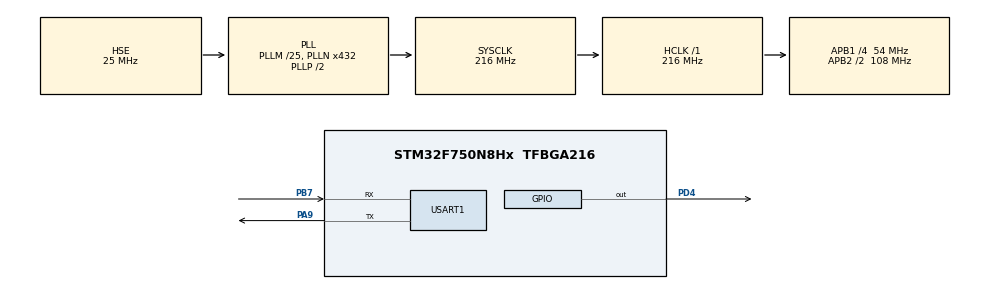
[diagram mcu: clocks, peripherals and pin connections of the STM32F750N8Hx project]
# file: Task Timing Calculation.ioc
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FREERTOS.Tasks01=defaultTask,24,128,StartDefaultTask,Default,NULL,Dynamic,NULL,NULL
Mcu.Family=STM32F7
Mcu.Name=STM32F750N8Hx
Mcu.Package=TFBGA216
NVIC.PriorityGroup=NVIC_PRIORITYGROUP_4
NVIC.TIM1_UP_TIM10_IRQn=true\:15\:0\:false\:false\:true\:false\:false\:true
NVIC.TimeBase=TIM1_UP_TIM10_IRQn
NVIC.TimeBaseIP=TIM1
PA9.Mode=Asynchronous
PA9.Signal=USART1_TX
PB7.Mode=Asynchronous
PB7.Signal=USART1_RX
PD4.Signal=GPIO_Output
PH0/OSC_IN.Mode=HSE-External-Oscillator
PH0/OSC_IN.Signal=RCC_OSC_IN
PH1/OSC_OUT.Mode=HSE-External-Oscillator
PH1/OSC_OUT.Signal=RCC_OSC_OUT
ProjectManager.HeapSize=0x200
ProjectManager.StackSize=0x400
ProjectManager.TargetToolchain=EWARM V8.32
RCC.AHBFreq_Value=216000000
RCC.APB1CLKDivider=RCC_HCLK_DIV4
RCC.APB1Freq_Value=54000000
RCC.APB1TimFreq_Value=108000000
RCC.APB2CLKDivider=RCC_HCLK_DIV2
RCC.APB2Freq_Value=108000000
RCC.APB2TimFreq_Value=216000000
RCC.CortexFreq_Value=216000000
RCC.HCLKFreq_Value=216000000
RCC.HSE_VALUE=25000000
RCC.HSI_VALUE=16000000
RCC.PLL48CLockSelection=RCC_CLK48SOURCE_PLLSAIP
RCC.PLLI2SN=100
RCC.PLLM=25
RCC.PLLN=432
RCC.PLLQ=9
RCC.PLLSAIN=384
RCC.PLLSAIP=RCC_PLLSAIP_DIV8
RCC.PLLSAIR=5
RCC.PLLSourceVirtual=RCC_PLLSOURCE_HSE
RCC.SDMMCClockSelection=RCC_SDMMC1CLKSOURCE_CLK48
RCC.SYSCLKFreq_VALUE=216000000
RCC.SYSCLKSource=RCC_SYSCLKSOURCE_PLLCLK
RCC.USBFreq_Value=48000000
RCC.VCOOutputFreq_Value=432000000
USART1.VirtualMode-Asynchronous=VM_ASYNC
VP_FREERTOS_VS_CMSIS_V2.Mode=CMSIS_V2
VP_SYS_VS_tim1.Mode=TIM1
board=STM32F7508-DK

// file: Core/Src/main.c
/* USER CODE BEGIN Header */
/**
  ******************************************************************************
  * @file           : main.c
  * @brief          : Main program body
  ******************************************************************************
  * @attention
  *
  * Copyright (c) 2025 STMicroelectronics.
  * All rights reserved.
  *
  ******************************************************************************
  */
/* USER CODE END Header */

#include "main.h"
#include "cmsis_os.h"
#include <string.h>
#include <stdio.h>

typedef void (*TaskBlockFunc)(void);

UART_HandleTypeDef huart1;

/* USER CODE BEGIN PV */
volatile uint32_t counter1 = 0;
volatile uint32_t counter2 = 0;
volatile uint32_t result = 0;
/* USER CODE END PV */

void SystemClock_Config(void);
static void MX_GPIO_Init(void);
static void MX_USART1_UART_Init(void);

void Task1(void *pvParameters);
void Task2(void *pvParameters);
void Task3(void *pvParameters);
void Task4(void *pvParameters);

/* USER CODE BEGIN 0 */
// Simple UART print function
void uart_print(const char *msg)
{
    HAL_UART_Transmit(&huart1, (uint8_t*)msg, strlen(msg), HAL_MAX_DELAY);
}

// Print number with description
void uart_print_num(const char *desc, uint32_t num)
{
    char buf[64];
    snprintf(buf, sizeof(buf), "%s %lu ms\r\n", desc, num);
    uart_print(buf);
}

// Profile a single block
void profile_block(const char *desc, TaskBlockFunc func)
{
    uint32_t start = HAL_GetTick();
    func();
    uint32_t end = HAL_GetTick();
    uart_print_num(desc, end - start);
}

// Profile entire task iteration
void profile_task(const char *task_name, TaskBlockFunc func)
{
    uint32_t start = HAL_GetTick();
    func();
    uint32_t end = HAL_GetTick();

    char buf[128];
    snprintf(buf, sizeof(buf), "%s total iteration took %lu ms\r\n\r\n", task_name, end - start);
    uart_print(buf);
}

/* Task logic */
void task1_logic(void)
{
    HAL_GPIO_WritePin(GPIOD, GPIO_PIN_4, GPIO_PIN_SET);
    vTaskDelay(pdMS_TO_TICKS(100));
    HAL_GPIO_WritePin(GPIOD, GPIO_PIN_4, GPIO_PIN_RESET);
    vTaskDelay(pdMS_TO_TICKS(100));
}

void task2_logic(void)
{
    counter1++;
    vTaskDelay(pdMS_TO_TICKS(200));
    counter2 += 2;
    vTaskDelay(pdMS_TO_TICKS(200));
}

void task3_logic(void)
{
    result = counter1 * counter2;
    vTaskDelay(pdMS_TO_TICKS(500));
}

void task4_logic(void)
{
    HAL_GPIO_WritePin(GPIOD, GPIO_PIN_4, GPIO_PIN_SET);
    vTaskDelay(pdMS_TO_TICKS(1000));
    HAL_GPIO_WritePin(GPIOD, GPIO_PIN_4, GPIO_PIN_RESET);
    vTaskDelay(pdMS_TO_TICKS(1000));
}
/* USER CODE END 0 */

/* USER CODE BEGIN 2 */
void Task1(void *pvParameters)
{
    while(1)
    {
        profile_task("Task1", task1_logic);
    }
}

void Task2(void *pvParameters)
{
    while(1)
    {
        profile_task("Task2", task2_logic);
    }
}

void Task3(void *pvParameters)
{
    while(1)
    {
        profile_task("Task3", task3_logic);
    }
}

void Task4(void *pvParameters)
{
    while(1)
    {
        profile_task("Task4", task4_logic);
    }
}
int main(void)
{

  /* MCU Configuration--------------------------------------------------------*/

  /* Reset of all peripherals, Initializes the Flash interface and the Systick. */
  HAL_Init();

  /* Configure the system clock */
  SystemClock_Config();

  /* Initialize all configured peripherals */
  MX_GPIO_Init();
  MX_USART1_UART_Init();

   // Create tasks
    xTaskCreate(Task1, "LED Fast", 256, NULL, 2, NULL);
    xTaskCreate(Task2, "Counter", 256, NULL, 1, NULL);
    xTaskCreate(Task3, "Compute", 256, NULL, 1, NULL);
    xTaskCreate(Task4, "LED Slow", 256, NULL, 1, NULL);

    vTaskStartScheduler(); // Start FreeRTOS

  while (1)
  {

  }
}

void SystemClock_Config(void)
{
  RCC_OscInitTypeDef RCC_OscInitStruct = {0};
  RCC_ClkInitTypeDef RCC_ClkInitStruct = {0};

  /** Configure the main internal regulator output voltage
  */
  __HAL_RCC_PWR_CLK_ENABLE();
  __HAL_PWR_VOLTAGESCALING_CONFIG(PWR_REGULATOR_VOLTAGE_SCALE1);
  /** Initializes the RCC Oscillators according to the specified parameters
  * in the RCC_OscInitTypeDef structure.
  */
  RCC_OscInitStruct.OscillatorType = RCC_OSCILLATORTYPE_HSE;
  RCC_OscInitStruct.HSEState = RCC_HSE_ON;
  RCC_OscInitStruct.PLL.PLLState = RCC_PLL_ON;
  RCC_OscInitStruct.PLL.PLLSource = RCC_PLLSOURCE_HSE;
  RCC_OscInitStruct.PLL.PLLM = 25;
  RCC_OscInitStruct.PLL.PLLN = 432;
  RCC_OscInitStruct.PLL.PLLP = RCC_PLLP_DIV2;
  RCC_OscInitStruct.PLL.PLLQ = 9;
  if (HAL_RCC_OscConfig(&RCC_OscInitStruct) != HAL_OK)
  {
    Error_Handler();
  }
  /** Activate the Over-Drive mode
  */
  if (HAL_PWREx_EnableOverDrive() != HAL_OK)
  {
    Error_Handler();
  }
  /** Initializes the CPU, AHB and APB buses clocks
  */
  RCC_ClkInitStruct.ClockType = RCC_CLOCKTYPE_HCLK|RCC_CLOCKTYPE_SYSCLK
                              |RCC_CLOCKTYPE_PCLK1|RCC_CLOCKTYPE_PCLK2;
  RCC_ClkInitStruct.SYSCLKSource = RCC_SYSCLKSOURCE_PLLCLK;
  RCC_ClkInitStruct.AHBCLKDivider = RCC_SYSCLK_DIV1;
  RCC_ClkInitStruct.APB1CLKDivider = RCC_HCLK_DIV4;
  RCC_ClkInitStruct.APB2CLKDivider = RCC_HCLK_DIV2;

  if (HAL_RCC_ClockConfig(&RCC_ClkInitStruct, FLASH_LATENCY_7) != HAL_OK)
  {
    Error_Handler();
  }
}

static void MX_USART1_UART_Init(void)
{

  huart1.Instance = USART1;
  huart1.Init.BaudRate = 115200;
  huart1.Init.WordLength = UART_WORDLENGTH_8B;
  huart1.Init.StopBits = UART_STOPBITS_1;
  huart1.Init.Parity = UART_PARITY_NONE;
  huart1.Init.Mode = UART_MODE_TX_RX;
  huart1.Init.HwFlowCtl = UART_HWCONTROL_NONE;
  huart1.Init.OverSampling = UART_OVERSAMPLING_16;
  huart1.Init.OneBitSampling = UART_ONE_BIT_SAMPLE_DISABLE;
  huart1.AdvancedInit.AdvFeatureInit = UART_ADVFEATURE_NO_INIT;
  if (HAL_UART_Init(&huart1) != HAL_OK)
  {
    Error_Handler();
  }

}

static void MX_GPIO_Init(void)
{
  GPIO_InitTypeDef GPIO_InitStruct = {0};

  /* GPIO Ports Clock Enable */
  __HAL_RCC_GPIOB_CLK_ENABLE();
  __HAL_RCC_GPIOD_CLK_ENABLE();
  __HAL_RCC_GPIOA_CLK_ENABLE();
  __HAL_RCC_GPIOH_CLK_ENABLE();

  /*Configure GPIO pin Output Level */
  HAL_GPIO_WritePin(GPIOD, GPIO_PIN_4, GPIO_PIN_RESET);

  /*Configure GPIO pin : PD4 */
  GPIO_InitStruct.Pin = GPIO_PIN_4;
  GPIO_InitStruct.Mode = GPIO_MODE_OUTPUT_PP;
  GPIO_InitStruct.Pull = GPIO_NOPULL;
  GPIO_InitStruct.Speed = GPIO_SPEED_FREQ_LOW;
  HAL_GPIO_Init(GPIOD, &GPIO_InitStruct);

}

void StartDefaultTask(void *argument)
{
  for(;;)
  {
    osDelay(1);
  }
}

void HAL_TIM_PeriodElapsedCallback(TIM_HandleTypeDef *htim)
{
  if (htim->Instance == TIM1) {
    HAL_IncTick();
  }
}

void Error_Handler(void)
{
  __disable_irq();
  while (1)
  {
  }
}
